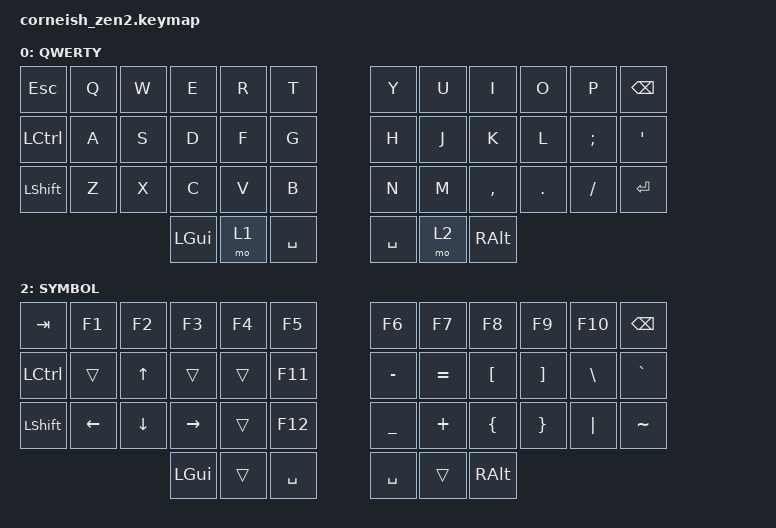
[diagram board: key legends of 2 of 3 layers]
#include <behaviors.dtsi>
#include <dt-bindings/zmk/keys.h>
#include <dt-bindings/zmk/bt.h>

/ {
    chosen {
        zmk,physical-layout = &foostan_corne_6col_layout;
        // zmk,physical-layout = &foostan_corne_5col_layout;
    };
};

/ {
    keymap {
                compatible = "zmk,keymap";

                default_layer {
                        label = "QWERTY";
// -----------------------------------------------------------------------------------------
// |  ESC |  Q  |  W  |  E  |  R  |  T  |   |  Y  |  U   |  I  |  O  |  P  | BKSP |
// | CTRL |  A  |  S  |  D  |  F  |  G  |   |  H  |  J   |  K  |  L  |  ;  |  '   |
// | SHFT |  Z  |  X  |  C  |  V  |  B  |   |  N  |  M   |  ,  |  .  |  /  | ENT  |
//                    | GUI | LWR | SPC |   | SPC | RSE  | ALT |
                        bindings = <
   &kp ESC   &kp Q &kp W &kp E &kp R &kp T   &kp Y &kp U  &kp I     &kp O   &kp P    &kp BSPC
   &kp LCTRL &kp A &kp S &kp D &kp F &kp G   &kp H &kp J  &kp K     &kp L   &kp SEMI &kp SQT
   &kp LSHFT &kp Z &kp X &kp C &kp V &kp B   &kp N &kp M  &kp COMMA &kp DOT &kp FSLH &kp RET
                  &kp LGUI &mo 1 &kp SPACE   &kp SPACE &mo 2 &kp RALT
                        >;
                };

        lower_layer {
            display-name = "NUMBER";
// -----------------------------------------------------------------------------------------
// |  TAB |   !   |   @   |   #   |   $   |   %   |   |   ^   |  &  |  *  |  (  |  )  | BSPC |
// | CTRL |   1   |   2   |   3   |   4   |   5   |   |   6   |  7  |  8  |  9  |  0  |Studio|
// | SHFT | BTCLR |  BT1  |  BT2  |  BT3  |  BT4  |   | PSCRN |     |     |     |     |      |
//                        | GUI   |       |  SPC  |   |  SPC  |     | ALT |
            bindings = <
&kp TAB    &kp EXCL    &kp AT        &kp HASH      &kp DLLR      &kp PRCNT       &kp CARET         &kp AMPS  &kp ASTRK  &kp LPAR  &kp RPAR  &kp BSPC
&kp LCTRL  &kp N1      &kp N2        &kp N3        &kp N4        &kp N5          &kp N6            &kp N7    &kp N8     &kp N9    &kp N0    &studio_unlock
&kp LSHFT  &bt BT_CLR  &bt BT_SEL 0  &bt BT_SEL 1  &bt BT_SEL 2  &bt BT_SEL 3    &kp Print Screen  &trans    &trans     &trans    &trans    &trans
                                     &kp LGUI      &trans        &kp SPACE       &kp SPACE         &trans    &kp RALT
            >;
        };

        raise_layer {
            display-name = "SYMBOL";
// -----------------------------------------------------------------------------------------
// |  TAB |  F1  |   F2  |  F3  |  F4  |   F5  |   |  F6  |  F7  |  F8  |  F9  |  F10  | BSPC |
// | CTRL |      |  UP   |      |      |  F11  |   |  -   |  =   |  [   |  ]   |   \   |  `   |
// | SHFT |  LFT |  DWN  |  RGT |      |  F12  |   |  _   |  +   |  {   |  }   |  "|"  |  ~   |
//                       |  GUI |      |  SPC  |   |  SPC |      | ALT  |
            bindings = <
&kp  TAB  &kp F1   &kp F2   &kp F3      &kp F4   &kp F5      &kp F6    &kp F7    &kp F8    &kp F9   &kp F10  &kp BSPC
&kp LCTRL &trans   &kp UP   &trans      &trans   &kp F11     &kp MINUS &kp EQUAL &kp LBKT  &kp RBKT &kp BSLH &kp GRAVE
&kp LSHFT &kp LEFT &kp DOWN &kp RIGHT   &trans   &kp F12     &kp UNDER &kp PLUS  &kp LBRC  &kp RBRC &kp PIPE &kp TILDE
                            &kp LGUI    &trans   &kp SPACE   &kp SPACE &trans    &kp RALT
            >;
        };
    };
};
